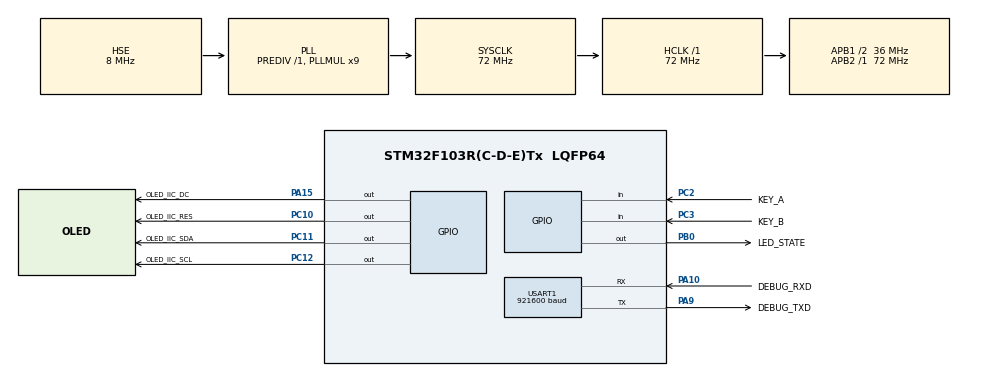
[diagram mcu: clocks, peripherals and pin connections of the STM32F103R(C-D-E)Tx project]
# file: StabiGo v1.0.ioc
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Dma.Request0=USART1_RX
Dma.Request1=USART1_TX
Dma.USART1_RX.0.Direction=DMA_PERIPH_TO_MEMORY
Dma.USART1_RX.0.Instance=DMA1_Channel5
Dma.USART1_RX.0.MemDataAlignment=DMA_MDATAALIGN_BYTE
Dma.USART1_RX.0.MemInc=DMA_MINC_ENABLE
Dma.USART1_RX.0.Mode=DMA_CIRCULAR
Dma.USART1_RX.0.PeriphDataAlignment=DMA_PDATAALIGN_BYTE
Dma.USART1_RX.0.PeriphInc=DMA_PINC_DISABLE
Dma.USART1_RX.0.Priority=DMA_PRIORITY_HIGH
Dma.USART1_TX.1.Direction=DMA_MEMORY_TO_PERIPH
Dma.USART1_TX.1.Instance=DMA1_Channel4
Dma.USART1_TX.1.MemDataAlignment=DMA_MDATAALIGN_BYTE
Dma.USART1_TX.1.MemInc=DMA_MINC_ENABLE
Dma.USART1_TX.1.Mode=DMA_NORMAL
Dma.USART1_TX.1.PeriphDataAlignment=DMA_PDATAALIGN_BYTE
Dma.USART1_TX.1.PeriphInc=DMA_PINC_DISABLE
Dma.USART1_TX.1.Priority=DMA_PRIORITY_MEDIUM
Mcu.Family=STM32F1
Mcu.Name=STM32F103R(C-D-E)Tx
Mcu.Package=LQFP64
NVIC.DMA1_Channel4_IRQn=true\:0\:0\:false\:false\:true\:false\:true\:true
NVIC.DMA1_Channel5_IRQn=true\:0\:0\:false\:false\:true\:false\:true\:true
NVIC.PriorityGroup=NVIC_PRIORITYGROUP_4
NVIC.USART1_IRQn=true\:0\:0\:false\:false\:true\:true\:true\:true
PA10.GPIO_Label=DEBUG_RXD
PA10.Mode=Asynchronous
PA10.Signal=USART1_RX
PA13.Mode=Serial_Wire
PA13.Signal=SYS_JTMS-SWDIO
PA14.Mode=Serial_Wire
PA14.Signal=SYS_JTCK-SWCLK
PA15.GPIO_Label=OLED_IIC_DC
PA15.GPIO_Speed=GPIO_SPEED_FREQ_MEDIUM
PA15.Signal=GPIO_Output
PA9.GPIO_Label=DEBUG_TXD
PA9.Mode=Asynchronous
PA9.Signal=USART1_TX
PB0.GPIO_Label=LED_STATE
PB0.GPIO_Speed=GPIO_SPEED_FREQ_MEDIUM
PB0.Signal=GPIO_Output
PC10.GPIO_Label=OLED_IIC_RES
PC10.GPIO_Speed=GPIO_SPEED_FREQ_MEDIUM
PC10.Signal=GPIO_Output
PC11.GPIO_Label=OLED_IIC_SDA
PC11.GPIO_ModeDefaultOutputPP=GPIO_MODE_OUTPUT_OD
PC11.GPIO_PuPd=GPIO_NOPULL
PC11.GPIO_Speed=GPIO_SPEED_FREQ_HIGH
PC11.Signal=GPIO_Output
PC12.GPIO_Label=OLED_IIC_SCL
PC12.GPIO_ModeDefaultOutputPP=GPIO_MODE_OUTPUT_OD
PC12.GPIO_PuPd=GPIO_NOPULL
PC12.GPIO_Speed=GPIO_SPEED_FREQ_HIGH
PC12.Signal=GPIO_Output
PC2.GPIO_Label=KEY_A
PC2.GPIO_PuPd=GPIO_PULLUP
PC2.Signal=GPIO_Input
PC3.GPIO_Label=KEY_B
PC3.GPIO_PuPd=GPIO_PULLUP
PC3.Signal=GPIO_Input
PD0-OSC_IN.Mode=HSE-External-Oscillator
PD0-OSC_IN.Signal=RCC_OSC_IN
PD1-OSC_OUT.Mode=HSE-External-Oscillator
PD1-OSC_OUT.Signal=RCC_OSC_OUT
ProjectManager.HeapSize=0x200
ProjectManager.StackSize=0x400
ProjectManager.TargetToolchain=MDK-ARM V5.32
RCC.AHBFreq_Value=72000000
RCC.APB1CLKDivider=RCC_HCLK_DIV2
RCC.APB1Freq_Value=36000000
RCC.APB1TimFreq_Value=72000000
RCC.APB2Freq_Value=72000000
RCC.APB2TimFreq_Value=72000000
RCC.HCLKFreq_Value=72000000
RCC.PLLMUL=RCC_PLL_MUL9
RCC.PLLSourceVirtual=RCC_PLLSOURCE_HSE
RCC.SYSCLKFreq_VALUE=72000000
RCC.SYSCLKSource=RCC_SYSCLKSOURCE_PLLCLK
RCC.USBFreq_Value=72000000
TIM6.AutoReloadPreload=TIM_AUTORELOAD_PRELOAD_ENABLE
TIM6.Prescaler=71
USART1.BaudRate=921600
USART1.VirtualMode=VM_ASYNC
VP_TIM6_VS_ClockSourceINT.Mode=Enable_Timer
board=custom

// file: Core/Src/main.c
/* USER CODE BEGIN Header */
/**
  ******************************************************************************
  * @file           : main.c
  * @brief          : Main program body
  ******************************************************************************
  * @attention
  *
  * Copyright (c) 2026 STMicroelectronics.
  * All rights reserved.
  *
  * This software is licensed under terms that can be found in the LICENSE file
  * in the root directory of this software component.
  * If no LICENSE file comes with this software, it is provided AS-IS.
  *
  ******************************************************************************
  */
/* USER CODE END Header */
#include "main.h"
#include "dma.h"
#include "tim.h"
#include "usart.h"
#include "gpio.h"

/* USER CODE BEGIN Includes */
#include "Board.h"

/* USER CODE END Includes */

void SystemClock_Config(void);

int main(void)
{

  /* MCU Configuration--------------------------------------------------------*/

  /* Reset of all peripherals, Initializes the Flash interface and the Systick. */
  HAL_Init();

  /* Configure the system clock */
  SystemClock_Config();

  /* Initialize all configured peripherals */
  MX_GPIO_Init();
  MX_DMA_Init();
  MX_USART1_UART_Init();
  MX_TIM6_Init();
  /* USER CODE BEGIN 2 */
  BoardInit();

  /* USER CODE END 2 */

  /* Infinite loop */
  while (1)
  {

    /* USER CODE BEGIN 3 */
    System_Main_Loop();
  }
  /* USER CODE END 3 */
}

void SystemClock_Config(void)
{
  RCC_OscInitTypeDef RCC_OscInitStruct = {0};
  RCC_ClkInitTypeDef RCC_ClkInitStruct = {0};

  /** Initializes the RCC Oscillators according to the specified parameters
  * in the RCC_OscInitTypeDef structure.
  */
  RCC_OscInitStruct.OscillatorType = RCC_OSCILLATORTYPE_HSE;
  RCC_OscInitStruct.HSEState = RCC_HSE_ON;
  RCC_OscInitStruct.HSEPredivValue = RCC_HSE_PREDIV_DIV1;
  RCC_OscInitStruct.HSIState = RCC_HSI_ON;
  RCC_OscInitStruct.PLL.PLLState = RCC_PLL_ON;
  RCC_OscInitStruct.PLL.PLLSource = RCC_PLLSOURCE_HSE;
  RCC_OscInitStruct.PLL.PLLMUL = RCC_PLL_MUL9;
  if (HAL_RCC_OscConfig(&RCC_OscInitStruct) != HAL_OK)
  {
    Error_Handler();
  }

  /** Initializes the CPU, AHB and APB buses clocks
  */
  RCC_ClkInitStruct.ClockType = RCC_CLOCKTYPE_HCLK|RCC_CLOCKTYPE_SYSCLK
                              |RCC_CLOCKTYPE_PCLK1|RCC_CLOCKTYPE_PCLK2;
  RCC_ClkInitStruct.SYSCLKSource = RCC_SYSCLKSOURCE_PLLCLK;
  RCC_ClkInitStruct.AHBCLKDivider = RCC_SYSCLK_DIV1;
  RCC_ClkInitStruct.APB1CLKDivider = RCC_HCLK_DIV2;
  RCC_ClkInitStruct.APB2CLKDivider = RCC_HCLK_DIV1;

  if (HAL_RCC_ClockConfig(&RCC_ClkInitStruct, FLASH_LATENCY_2) != HAL_OK)
  {
    Error_Handler();
  }
}

void Error_Handler(void)
{
  __disable_irq();
  while (1)
  {
  }
}
